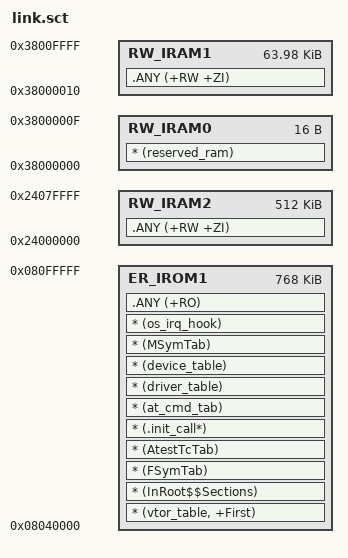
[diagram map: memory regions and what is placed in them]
; *************************************************************
; *** Scatter-Loading Description File generated by uVision ***
; *************************************************************

LR_IROM1 0x08040000 0x000c0000  {    ; load region size_region
  ER_IROM1 0x08040000 0x000c0000  {  ; load address = execution address
   * (vtor_table, +First)
   * (InRoot$$Sections)
   * (FSymTab)
   * (AtestTcTab)
   * (.init_call*)
   * (at_cmd_tab)
   * (driver_table)
   * (device_table)
   * (MSymTab)
   * (os_irq_hook)
   .ANY (+RO)
  }

  RW_IRAM0 0x38000000 0x10  {  ; RW data
   * (reserved_ram)
  }

  RW_IRAM1 0x38000010 0xfff0 {  ; RW data
   .ANY (+RW +ZI)
  }
  RW_IRAM2 0x24000000 0x00080000  {  ; RW data
   .ANY (+RW +ZI)
  }
}

